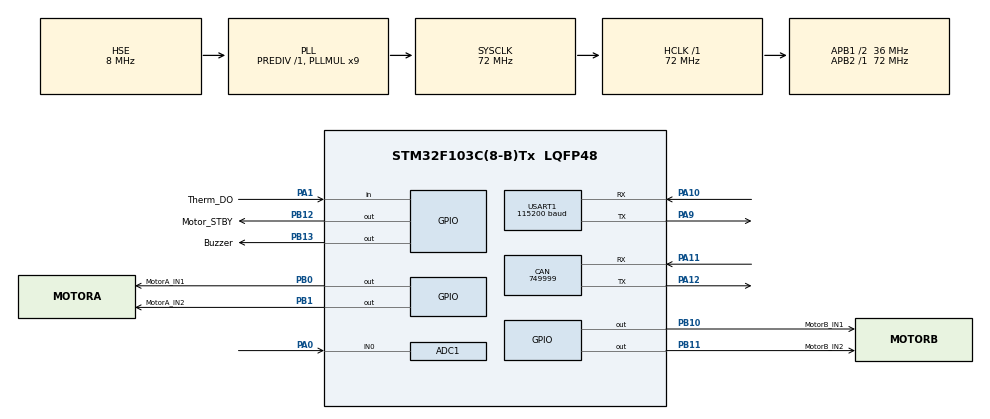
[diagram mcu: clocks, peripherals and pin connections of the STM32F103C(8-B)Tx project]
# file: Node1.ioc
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ADC1.Channel-0\#ChannelRegularConversion=ADC_CHANNEL_0
ADC1.ContinuousConvMode=DISABLE
ADC1.NbrOfConversionFlag=1
ADC1.Rank-0\#Rank=1
ADC1.SamplingTime-0\#SamplingTime=ADC_SAMPLETIME_239CYCLES_5
ADC1.master=1
CAN.CalculateBaudRate=749999
CAN.CalculateTimeBit=1333
CAN.CalculateTimeQuantum=444.44444444444446
Mcu.Family=STM32F1
Mcu.Name=STM32F103C(8-B)Tx
Mcu.Package=LQFP48
NVIC.PriorityGroup=NVIC_PRIORITYGROUP_4
PA0-WKUP.Signal=ADCx_IN0
PA1.GPIO_Label=Therm_DO
PA1.GPIO_PuPd=GPIO_PULLDOWN
PA1.Signal=GPIO_Input
PA10.Mode=Asynchronous
PA10.Signal=USART1_RX
PA11.Mode=CAN_Activate
PA11.Signal=CAN_RX
PA12.Mode=CAN_Activate
PA12.Signal=CAN_TX
PA13.Mode=Serial_Wire
PA13.Signal=SYS_JTMS-SWDIO
PA14.Mode=Serial_Wire
PA14.Signal=SYS_JTCK-SWCLK
PA9.Mode=Asynchronous
PA9.Signal=USART1_TX
PB0.GPIO_Label=MotorA_IN1
PB0.Signal=GPIO_Output
PB1.GPIO_Label=MotorA_IN2
PB1.Signal=GPIO_Output
PB10.GPIO_Label=MotorB_IN1
PB10.Signal=GPIO_Output
PB11.GPIO_Label=MotorB_IN2
PB11.Signal=GPIO_Output
PB12.GPIO_Label=Motor_STBY
PB12.GPIO_PuPd=GPIO_PULLDOWN
PB12.Signal=GPIO_Output
PB13.GPIO_Label=Buzzer
PB13.GPIO_PuPd=GPIO_PULLUP
PB13.Signal=GPIO_Output
PD0-OSC_IN.Mode=HSE-External-Oscillator
PD0-OSC_IN.Signal=RCC_OSC_IN
PD1-OSC_OUT.Mode=HSE-External-Oscillator
PD1-OSC_OUT.Signal=RCC_OSC_OUT
ProjectManager.HeapSize=0x200
ProjectManager.StackSize=0x400
ProjectManager.TargetToolchain=CMake
RCC.ADCPresc=RCC_ADCPCLK2_DIV6
RCC.AHBFreq_Value=72000000
RCC.APB1CLKDivider=RCC_HCLK_DIV2
RCC.APB1Freq_Value=36000000
RCC.APB1TimFreq_Value=72000000
RCC.APB2Freq_Value=72000000
RCC.APB2TimFreq_Value=72000000
RCC.HCLKFreq_Value=72000000
RCC.PLLMUL=RCC_PLL_MUL9
RCC.PLLSourceVirtual=RCC_PLLSOURCE_HSE
RCC.SYSCLKFreq_VALUE=72000000
RCC.SYSCLKSource=RCC_SYSCLKSOURCE_PLLCLK
RCC.USBFreq_Value=72000000
SH.ADCx_IN0.0=ADC1_IN0,IN0
USART1.BaudRate=115200
USART1.Parity=PARITY_NONE
USART1.StopBits=STOPBITS_1
USART1.VirtualMode=VM_ASYNC
USART1.WordLength=WORDLENGTH_8B
board=custom

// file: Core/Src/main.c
/* USER CODE BEGIN Header */
/**
  ******************************************************************************
  * @file           : main.c
  * @brief          : Main program body
  ******************************************************************************
  * @attention
  *
  * Copyright (c) 2026 STMicroelectronics.
  * All rights reserved.
  *
  * This software is licensed under terms that can be found in the LICENSE file
  * in the root directory of this software component.
  * If no LICENSE file comes with this software, it is provided AS-IS.
  *
  ******************************************************************************
  */
/* USER CODE END Header */
#include "main.h"

/* USER CODE BEGIN Includes */
#include "node1_app.h"   /* 业务/调度/HAL 的对外接口（零 HAL 依赖那一层） */
/* USER CODE END Includes */

ADC_HandleTypeDef hadc1;

CAN_HandleTypeDef hcan;

UART_HandleTypeDef huart1;

void SystemClock_Config(void);
static void MX_GPIO_Init(void);
static void MX_ADC1_Init(void);
static void MX_USART1_UART_Init(void);
static void MX_CAN_Init(void);

int main(void)
{

  /* MCU Configuration--------------------------------------------------------*/

  /* Reset of all peripherals, Initializes the Flash interface and the Systick. */
  HAL_Init();

  /* Configure the system clock */
  SystemClock_Config();

  /* Initialize all configured peripherals */
  MX_GPIO_Init();
  MX_ADC1_Init();
  MX_USART1_UART_Init();
  MX_CAN_Init();
  /* USER CODE BEGIN 2 */
  /* 把控制权交给节点固件：内部会初始化 ADC / TIM4 PWM / USART1 / bxCAN / IWDG，
   * 然后进入常驻主循环（裸机 super-loop，1ms 步进）。
   * 本函数**不返回**，因此下面 CubeMX 的 while(1) 不会被走到——保留它是为了让
   * CubeMX 重新生成代码时结构不变（用户代码段不会被覆盖）。 */
  node1_firmware_run();
  /* USER CODE END 2 */

  /* Infinite loop */
  while (1)
  {

  }
}

void SystemClock_Config(void)
{
  RCC_OscInitTypeDef RCC_OscInitStruct = {0};
  RCC_ClkInitTypeDef RCC_ClkInitStruct = {0};
  RCC_PeriphCLKInitTypeDef PeriphClkInit = {0};

  /** Initializes the RCC Oscillators according to the specified parameters
  * in the RCC_OscInitTypeDef structure.
  */
  RCC_OscInitStruct.OscillatorType = RCC_OSCILLATORTYPE_HSE;
  RCC_OscInitStruct.HSEState = RCC_HSE_ON;
  RCC_OscInitStruct.HSEPredivValue = RCC_HSE_PREDIV_DIV1;
  RCC_OscInitStruct.HSIState = RCC_HSI_ON;
  RCC_OscInitStruct.PLL.PLLState = RCC_PLL_ON;
  RCC_OscInitStruct.PLL.PLLSource = RCC_PLLSOURCE_HSE;
  RCC_OscInitStruct.PLL.PLLMUL = RCC_PLL_MUL9;
  if (HAL_RCC_OscConfig(&RCC_OscInitStruct) != HAL_OK)
  {
    Error_Handler();
  }

  /** Initializes the CPU, AHB and APB buses clocks
  */
  RCC_ClkInitStruct.ClockType = RCC_CLOCKTYPE_HCLK|RCC_CLOCKTYPE_SYSCLK
                              |RCC_CLOCKTYPE_PCLK1|RCC_CLOCKTYPE_PCLK2;
  RCC_ClkInitStruct.SYSCLKSource = RCC_SYSCLKSOURCE_PLLCLK;
  RCC_ClkInitStruct.AHBCLKDivider = RCC_SYSCLK_DIV1;
  RCC_ClkInitStruct.APB1CLKDivider = RCC_HCLK_DIV2;
  RCC_ClkInitStruct.APB2CLKDivider = RCC_HCLK_DIV1;

  if (HAL_RCC_ClockConfig(&RCC_ClkInitStruct, FLASH_LATENCY_2) != HAL_OK)
  {
    Error_Handler();
  }
  PeriphClkInit.PeriphClockSelection = RCC_PERIPHCLK_ADC;
  PeriphClkInit.AdcClockSelection = RCC_ADCPCLK2_DIV6;
  if (HAL_RCCEx_PeriphCLKConfig(&PeriphClkInit) != HAL_OK)
  {
    Error_Handler();
  }
}

static void MX_ADC1_Init(void)
{

  ADC_ChannelConfTypeDef sConfig = {0};

  /** Common config
  */
  hadc1.Instance = ADC1;
  hadc1.Init.ScanConvMode = ADC_SCAN_DISABLE;
  hadc1.Init.ContinuousConvMode = DISABLE;
  hadc1.Init.DiscontinuousConvMode = DISABLE;
  hadc1.Init.ExternalTrigConv = ADC_SOFTWARE_START;
  hadc1.Init.DataAlign = ADC_DATAALIGN_RIGHT;
  hadc1.Init.NbrOfConversion = 1;
  if (HAL_ADC_Init(&hadc1) != HAL_OK)
  {
    Error_Handler();
  }

  /** Configure Regular Channel
  */
  sConfig.Channel = ADC_CHANNEL_0;
  sConfig.Rank = ADC_REGULAR_RANK_1;
  sConfig.SamplingTime = ADC_SAMPLETIME_1CYCLE_5;
  if (HAL_ADC_ConfigChannel(&hadc1, &sConfig) != HAL_OK)
  {
    Error_Handler();
  }

}

static void MX_CAN_Init(void)
{

  hcan.Instance = CAN1;
  hcan.Init.Prescaler = 16;
  hcan.Init.Mode = CAN_MODE_NORMAL;
  hcan.Init.SyncJumpWidth = CAN_SJW_1TQ;
  hcan.Init.TimeSeg1 = CAN_BS1_1TQ;
  hcan.Init.TimeSeg2 = CAN_BS2_1TQ;
  hcan.Init.TimeTriggeredMode = DISABLE;
  hcan.Init.AutoBusOff = DISABLE;
  hcan.Init.AutoWakeUp = DISABLE;
  hcan.Init.AutoRetransmission = DISABLE;
  hcan.Init.ReceiveFifoLocked = DISABLE;
  hcan.Init.TransmitFifoPriority = DISABLE;
  if (HAL_CAN_Init(&hcan) != HAL_OK)
  {
    Error_Handler();
  }

}

static void MX_USART1_UART_Init(void)
{

  huart1.Instance = USART1;
  huart1.Init.BaudRate = 115200;
  huart1.Init.WordLength = UART_WORDLENGTH_8B;
  huart1.Init.StopBits = UART_STOPBITS_1;
  huart1.Init.Parity = UART_PARITY_NONE;
  huart1.Init.Mode = UART_MODE_TX_RX;
  huart1.Init.HwFlowCtl = UART_HWCONTROL_NONE;
  huart1.Init.OverSampling = UART_OVERSAMPLING_16;
  if (HAL_UART_Init(&huart1) != HAL_OK)
  {
    Error_Handler();
  }

}

static void MX_GPIO_Init(void)
{
  GPIO_InitTypeDef GPIO_InitStruct = {0};

  /* GPIO Ports Clock Enable */
  __HAL_RCC_GPIOD_CLK_ENABLE();
  __HAL_RCC_GPIOA_CLK_ENABLE();
  __HAL_RCC_GPIOB_CLK_ENABLE();

  /*Configure GPIO pin Output Level */
  HAL_GPIO_WritePin(GPIOB, MotorA_IN1_Pin|MotorA_IN2_Pin|MotorB_IN1_Pin|MotorB_IN2_Pin
                          |Motor_STBY_Pin|Buzzer_Pin, GPIO_PIN_RESET);

  /*Configure GPIO pin : Therm_DO_Pin */
  GPIO_InitStruct.Pin = Therm_DO_Pin;
  GPIO_InitStruct.Mode = GPIO_MODE_INPUT;
  GPIO_InitStruct.Pull = GPIO_PULLDOWN;
  HAL_GPIO_Init(Therm_DO_GPIO_Port, &GPIO_InitStruct);

  /*Configure GPIO pins : MotorA_IN1_Pin MotorA_IN2_Pin MotorB_IN1_Pin MotorB_IN2_Pin */
  GPIO_InitStruct.Pin = MotorA_IN1_Pin|MotorA_IN2_Pin|MotorB_IN1_Pin|MotorB_IN2_Pin;
  GPIO_InitStruct.Mode = GPIO_MODE_OUTPUT_PP;
  GPIO_InitStruct.Pull = GPIO_NOPULL;
  GPIO_InitStruct.Speed = GPIO_SPEED_FREQ_LOW;
  HAL_GPIO_Init(GPIOB, &GPIO_InitStruct);

  /*Configure GPIO pin : Motor_STBY_Pin */
  GPIO_InitStruct.Pin = Motor_STBY_Pin;
  GPIO_InitStruct.Mode = GPIO_MODE_OUTPUT_PP;
  GPIO_InitStruct.Pull = GPIO_PULLDOWN;
  GPIO_InitStruct.Speed = GPIO_SPEED_FREQ_LOW;
  HAL_GPIO_Init(Motor_STBY_GPIO_Port, &GPIO_InitStruct);

  /*Configure GPIO pin : Buzzer_Pin */
  GPIO_InitStruct.Pin = Buzzer_Pin;
  GPIO_InitStruct.Mode = GPIO_MODE_OUTPUT_PP;
  GPIO_InitStruct.Pull = GPIO_PULLUP;
  GPIO_InitStruct.Speed = GPIO_SPEED_FREQ_LOW;
  HAL_GPIO_Init(Buzzer_GPIO_Port, &GPIO_InitStruct);

}

void Error_Handler(void)
{
  __disable_irq();
  while (1)
  {
  }
}
